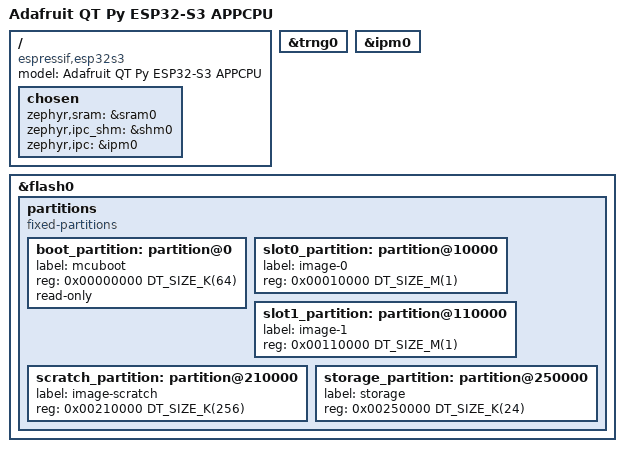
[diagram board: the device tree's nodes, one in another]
/dts-v1/;

#include <espressif/esp32s3/esp32s3_appcpu.dtsi>
 
/ {
	model = "Adafruit QT Py ESP32-S3 APPCPU";
	compatible = "espressif,esp32s3";

	chosen {
		zephyr,sram = &sram0;
		zephyr,ipc_shm = &shm0;
		zephyr,ipc = &ipm0;
	};
};

&trng0 {
	status = "okay";
};

&ipm0 {
	status = "okay";
};

&flash0 {
	status = "okay";
	partitions {
		compatible = "fixed-partitions";
		#address-cells = <1>;
		#size-cells = <1>;

		boot_partition: partition@0 {
			label = "mcuboot";
			reg = <0x00000000 DT_SIZE_K(64)>;
			read-only;
		};

		slot0_partition: partition@10000 {
			label = "image-0";
			reg = <0x00010000 DT_SIZE_M(1)>;
		};

		slot1_partition: partition@110000 {
			label = "image-1";
			reg = <0x00110000 DT_SIZE_M(1)>;
		};

		scratch_partition: partition@210000 {
			label = "image-scratch";
			reg = <0x00210000 DT_SIZE_K(256)>;
		};

		storage_partition: partition@250000 {
			label = "storage";
			reg = <0x00250000 DT_SIZE_K(24)>;
		};
	};
};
